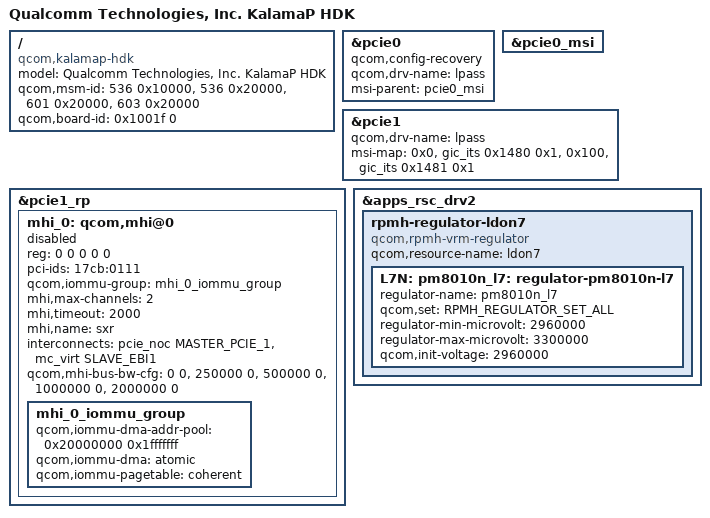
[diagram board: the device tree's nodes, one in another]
/dts-v1/;
/plugin/;

#include <dt-bindings/interconnect/qcom,kalama.h>
#include "kalamap-hdk.dtsi"
#include <dt-bindings/regulator/qcom,rpmh-regulator-levels.h>

/ {
	model = "Qualcomm Technologies, Inc. KalamaP HDK";
	compatible = "qcom,kalamap-hdk", "qcom,kalamap", "qcom,hdk";
	qcom,msm-id = <536 0x10000>, <536 0x20000>, <601 0x20000>, <603 0x20000>;
	qcom,board-id = <0x1001f 0>;
};

&pcie0 {
	qcom,config-recovery;
	qcom,drv-name = "lpass";
	msi-parent = <&pcie0_msi>;
};

&pcie0_msi {
	status = "ok";
};

&pcie1 {
	qcom,drv-name = "lpass";
	msi-map = <0x0 &gic_its 0x1480 0x1>,
		  <0x100 &gic_its 0x1481 0x1>; /* 32 event IDs */
};

&pcie1_rp {
	#address-cells = <5>;
	#size-cells = <0>;

	/*
	 *This property is needed only for SoC-to-SoC communication
	 *(EP mode support) on HDK platform.
	 */
	mhi_0: qcom,mhi@0 {
		reg = <0 0 0 0 0 >;

		status = "disabled";

		pci-ids = "17cb:0111";

		/* controller specific configuration */
		qcom,iommu-group = <&mhi_0_iommu_group>;

		/* mhi bus specific settings */
		mhi,max-channels = <2>;
		mhi,timeout = <2000>;
		mhi,name = "sxr";

		#address-cells = <1>;
		#size-cells = <1>;

		interconnects = <&pcie_noc MASTER_PCIE_1 &mc_virt SLAVE_EBI1>;
		interconnect-names = "pcie_to_ddr";

		qcom,mhi-bus-bw-cfg = <0 0>, /* no vote */
				<250000 0>, /* avg bw / AB: 2 GBps, peak bw / IB: no vote */
				<500000 0>, /* avg bw / AB: 4 GBps, peak bw / IB: no vote */
				<1000000 0>, /* avg bw / AB: 8 GBps, peak bw / IB: no vote */
				<2000000 0>; /* avg bw / AB: 16 GBps, peak bw / IB: no vote */

		mhi_0_iommu_group: mhi_0_iommu_group {
			qcom,iommu-dma-addr-pool = <0x20000000 0x1fffffff>;
			qcom,iommu-dma = "atomic";
			qcom,iommu-pagetable = "coherent";
		};
	};
};

&apps_rsc_drv2 {
	rpmh-regulator-ldon7 {
		compatible = "qcom,rpmh-vrm-regulator";
		qcom,resource-name = "ldon7";

		L7N: pm8010n_l7: regulator-pm8010n-l7 {
			regulator-name = "pm8010n_l7";
			qcom,set = <RPMH_REGULATOR_SET_ALL>;
			regulator-min-microvolt = <2960000>;
			regulator-max-microvolt = <3300000>;
			qcom,init-voltage = <2960000>;
		};
	};
};

